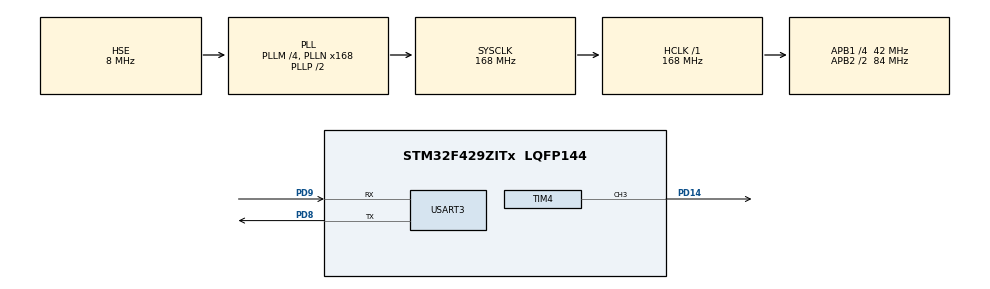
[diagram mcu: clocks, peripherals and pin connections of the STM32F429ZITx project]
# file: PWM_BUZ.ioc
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Mcu.Family=STM32F4
Mcu.Name=STM32F429ZITx
Mcu.Package=LQFP144
NVIC.PriorityGroup=NVIC_PRIORITYGROUP_4
NVIC.TIM4_IRQn=true\:0\:0\:false\:true\:true\:1\:true\:true\:true
NVIC.USART3_IRQn=true\:0\:0\:false\:true\:true\:2\:true\:true\:true
PC14/OSC32_IN.Mode=LSE-External-Oscillator
PC14/OSC32_IN.Signal=RCC_OSC32_IN
PC15/OSC32_OUT.Mode=LSE-External-Oscillator
PC15/OSC32_OUT.Signal=RCC_OSC32_OUT
PD14.Signal=S_TIM4_CH3
PD8.Mode=Asynchronous
PD8.Signal=USART3_TX
PD9.Mode=Asynchronous
PD9.Signal=USART3_RX
PH0/OSC_IN.Mode=HSE-External-Clock-Source
PH0/OSC_IN.Signal=RCC_OSC_IN
PH1/OSC_OUT.Mode=HSE-External-Clock-Source
PH1/OSC_OUT.Signal=RCC_OSC_OUT
ProjectManager.HeapSize=0x200
ProjectManager.StackSize=0x400
ProjectManager.TargetToolchain=STM32CubeIDE
RCC.48MHZClocksFreq_Value=84000000
RCC.AHBFreq_Value=168000000
RCC.APB1CLKDivider=RCC_HCLK_DIV4
RCC.APB1Freq_Value=42000000
RCC.APB1TimFreq_Value=84000000
RCC.APB2CLKDivider=RCC_HCLK_DIV2
RCC.APB2Freq_Value=84000000
RCC.APB2TimFreq_Value=168000000
RCC.CortexFreq_Value=168000000
RCC.HCLKFreq_Value=168000000
RCC.HSE_VALUE=8000000
RCC.HSI_VALUE=16000000
RCC.PLLM=4
RCC.PLLN=168
RCC.PLLSourceVirtual=RCC_PLLSOURCE_HSE
RCC.SYSCLKFreq_VALUE=168000000
RCC.SYSCLKSource=RCC_SYSCLKSOURCE_PLLCLK
RCC.VCOOutputFreq_Value=336000000
SH.S_TIM4_CH3.0=TIM4_CH3,PWM Generation3 CH3
TIM4.Channel-PWM\ Generation3\ CH3=TIM_CHANNEL_3
TIM4.Period=168-1
TIM4.Prescaler=0
TIM4.Pulse-PWM\ Generation3\ CH3=84-1
USART3.VirtualMode=VM_ASYNC
board=custom

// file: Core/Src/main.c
/* USER CODE BEGIN Header */
/**
  ******************************************************************************
  * @file           : main.c
  * @brief          : Main program body
  ******************************************************************************
  * @attention
  *
  * Copyright (c) 2023 STMicroelectronics.
  * All rights reserved.
  *
  * This software is licensed under terms that can be found in the LICENSE file
  * in the root directory of this software component.
  * If no LICENSE file comes with this software, it is provided AS-IS.
  *
  ******************************************************************************
  */
/* USER CODE END Header */
#include "main.h"

TIM_HandleTypeDef htim4;

UART_HandleTypeDef huart3;

/* USER CODE BEGIN PV */
typedef enum {
	N = 0,
    C = 956,
    D = 852,
    E = 758,
    F = 716,
    G = 638,
    A = 568,
    B = 506,
    C6 = 478
}_NOTE;

_NOTE note;
uint8_t rx_data=0;
uint32_t IRcalled=0;
/* USER CODE END PV */

void SystemClock_Config(void);
static void MX_GPIO_Init(void);
static void MX_TIM4_Init(void);
static void MX_USART3_UART_Init(void);
static void MX_NVIC_Init(void);
/* USER CODE BEGIN PFP */
void piano(_NOTE note);
_NOTE numtoscale(uint8_t strnum);

/* USER CODE END PFP */

/* USER CODE BEGIN 0 */
_NOTE numtoscale(uint8_t strnum){
	if(strnum=='1'){
		return C;
	}else if(strnum=='2'){
		return D;
	}else if(strnum=='3'){
		return E;
	}else if(strnum=='4'){
		return F;
	}else if(strnum=='5'){
		return G;
	}else if(strnum=='6'){
		return A;
	}else if(strnum=='7'){
		return B;
	}else if(strnum=='8'){
		return C6;
	}else
		return N;
}
void piano(_NOTE scale){

	HAL_TIM_PWM_Start(&htim4, TIM_CHANNEL_3);
	TIM4->PSC = scale;
//	TIM4->ARR = scale;
//	TIM4->CCR3 = TIM4->ARR / 2;
	HAL_Delay(300);
	HAL_TIM_PWM_Stop(&htim4, TIM_CHANNEL_3);

}
/* USER CODE END 0 */

int main(void)
{

  /* MCU Configuration--------------------------------------------------------*/

  /* Reset of all peripherals, Initializes the Flash interface and the Systick. */
  HAL_Init();

  /* Configure the system clock */
  SystemClock_Config();

  /* Initialize all configured peripherals */
  MX_GPIO_Init();
  MX_TIM4_Init();
  MX_USART3_UART_Init();

  /* Initialize interrupts */
  MX_NVIC_Init();
  /* USER CODE BEGIN 2 */
  //자동재생 피아노
  HAL_TIM_PWM_Start(&htim4, TIM_CHANNEL_3);	//PWM3 of TIM4 start BUZZ
  uint16_t bell[] = {G, E, E, F, D, D, C, D, E, F, G, G, G, G, E, E, E, F, D, D, C, E, G, G, E, E, E,
		  	  	  D, D, D, D, D, E, F, E, E, E, E, E, F, G, G, E, E, E, F, D, D, C, E, G, G, E, E, E};
  uint8_t bell_length = sizeof(bell)/sizeof(uint16_t);
  uint8_t interval[] = {10, 10, 100, 10, 10, 10, 10, 10, 10, 10, 10, 10, 244,
		  10, 10, 10, 10, 10, 10, 150, 10, 10, 10, 10, 10, 10, 244,
		  10, 10, 10, 10, 10, 10, 244,
		  10, 10, 10, 10, 10, 10, 244,
		  10, 10, 10, 10, 10, 10, 150, 10, 10, 10, 10, 10, 10, 244};

  //키보드로 입력해서 피아노치기
  HAL_UART_Receive_IT(&huart3, &rx_data, 1);
//  uint8_t test[8]={'1','2','3','4','5','6','7','8'};
  uint32_t temp;
  /* USER CODE END 2 */

  /* Infinite loop */
  /* USER CODE BEGIN WHILE */
  while (1)
  {
	  //bell 배열의 노래
//	  for(int i=0; i < bell_length; i++) {
//		  TIM4->PSC = bell[i];
//		  HAL_Delay(500);
//		  HAL_Delay(interval[i]);
//	  }
    /* USER CODE END WHILE */

    /* USER CODE BEGIN 3 */
	  //키보드 입력으로 계이름 치기
	  temp=IRcalled;
	  if(rx_data!=0){
		  note = numtoscale(rx_data);
		  piano(note);
		  if(temp==IRcalled){
			  rx_data=0;
		  }
	  }
  /* USER CODE END 3 */
}

void SystemClock_Config(void)
{
  RCC_OscInitTypeDef RCC_OscInitStruct = {0};
  RCC_ClkInitTypeDef RCC_ClkInitStruct = {0};

  /** Configure the main internal regulator output voltage
  */
  __HAL_RCC_PWR_CLK_ENABLE();
  __HAL_PWR_VOLTAGESCALING_CONFIG(PWR_REGULATOR_VOLTAGE_SCALE1);

  /** Initializes the RCC Oscillators according to the specified parameters
  * in the RCC_OscInitTypeDef structure.
  */
  RCC_OscInitStruct.OscillatorType = RCC_OSCILLATORTYPE_HSE;
  RCC_OscInitStruct.HSEState = RCC_HSE_BYPASS;
  RCC_OscInitStruct.PLL.PLLState = RCC_PLL_ON;
  RCC_OscInitStruct.PLL.PLLSource = RCC_PLLSOURCE_HSE;
  RCC_OscInitStruct.PLL.PLLM = 4;
  RCC_OscInitStruct.PLL.PLLN = 168;
  RCC_OscInitStruct.PLL.PLLP = RCC_PLLP_DIV2;
  RCC_OscInitStruct.PLL.PLLQ = 4;
  if (HAL_RCC_OscConfig(&RCC_OscInitStruct) != HAL_OK)
  {
    Error_Handler();
  }

  /** Initializes the CPU, AHB and APB buses clocks
  */
  RCC_ClkInitStruct.ClockType = RCC_CLOCKTYPE_HCLK|RCC_CLOCKTYPE_SYSCLK
                              |RCC_CLOCKTYPE_PCLK1|RCC_CLOCKTYPE_PCLK2;
  RCC_ClkInitStruct.SYSCLKSource = RCC_SYSCLKSOURCE_PLLCLK;
  RCC_ClkInitStruct.AHBCLKDivider = RCC_SYSCLK_DIV1;
  RCC_ClkInitStruct.APB1CLKDivider = RCC_HCLK_DIV4;
  RCC_ClkInitStruct.APB2CLKDivider = RCC_HCLK_DIV2;

  if (HAL_RCC_ClockConfig(&RCC_ClkInitStruct, FLASH_LATENCY_5) != HAL_OK)
  {
    Error_Handler();
  }
}

/**
  * @brief NVIC Configuration.
  * @retval None
  */
static void MX_NVIC_Init(void)
{
  /* TIM4_IRQn interrupt configuration */
  HAL_NVIC_SetPriority(TIM4_IRQn, 0, 0);
  HAL_NVIC_EnableIRQ(TIM4_IRQn);
  /* USART3_IRQn interrupt configuration */
  HAL_NVIC_SetPriority(USART3_IRQn, 0, 0);
  HAL_NVIC_EnableIRQ(USART3_IRQn);
}

static void MX_TIM4_Init(void)
{

  TIM_MasterConfigTypeDef sMasterConfig = {0};
  TIM_OC_InitTypeDef sConfigOC = {0};

  htim4.Instance = TIM4;
  htim4.Init.Prescaler = 0;
  htim4.Init.CounterMode = TIM_COUNTERMODE_UP;
  htim4.Init.Period = 168-1;
  htim4.Init.ClockDivision = TIM_CLOCKDIVISION_DIV1;
  htim4.Init.AutoReloadPreload = TIM_AUTORELOAD_PRELOAD_DISABLE;
  if (HAL_TIM_PWM_Init(&htim4) != HAL_OK)
  {
    Error_Handler();
  }
  sMasterConfig.MasterOutputTrigger = TIM_TRGO_RESET;
  sMasterConfig.MasterSlaveMode = TIM_MASTERSLAVEMODE_DISABLE;
  if (HAL_TIMEx_MasterConfigSynchronization(&htim4, &sMasterConfig) != HAL_OK)
  {
    Error_Handler();
  }
  sConfigOC.OCMode = TIM_OCMODE_PWM1;
  sConfigOC.Pulse = 84-1;
  sConfigOC.OCPolarity = TIM_OCPOLARITY_HIGH;
  sConfigOC.OCFastMode = TIM_OCFAST_DISABLE;
  if (HAL_TIM_PWM_ConfigChannel(&htim4, &sConfigOC, TIM_CHANNEL_3) != HAL_OK)
  {
    Error_Handler();
  }
  HAL_TIM_MspPostInit(&htim4);

}

static void MX_USART3_UART_Init(void)
{

  huart3.Instance = USART3;
  huart3.Init.BaudRate = 115200;
  huart3.Init.WordLength = UART_WORDLENGTH_8B;
  huart3.Init.StopBits = UART_STOPBITS_1;
  huart3.Init.Parity = UART_PARITY_NONE;
  huart3.Init.Mode = UART_MODE_TX_RX;
  huart3.Init.HwFlowCtl = UART_HWCONTROL_NONE;
  huart3.Init.OverSampling = UART_OVERSAMPLING_16;
  if (HAL_UART_Init(&huart3) != HAL_OK)
  {
    Error_Handler();
  }

}

static void MX_GPIO_Init(void)
{

  /* GPIO Ports Clock Enable */
  __HAL_RCC_GPIOC_CLK_ENABLE();
  __HAL_RCC_GPIOH_CLK_ENABLE();
  __HAL_RCC_GPIOD_CLK_ENABLE();

}

/* USER CODE BEGIN 4 */
void HAL_UART_RxCpltCallback(UART_HandleTypeDef *huart)
{
  if(huart->Instance == huart3.Instance){
	  HAL_UART_Receive_IT(&huart3, &rx_data, 1);
	  HAL_UART_Transmit(&huart3, &rx_data, 1, 10);

	  IRcalled++;

  }
}
/* USER CODE END 4 */

void Error_Handler(void)
{
  __disable_irq();
  while (1)
  {
  }
}
